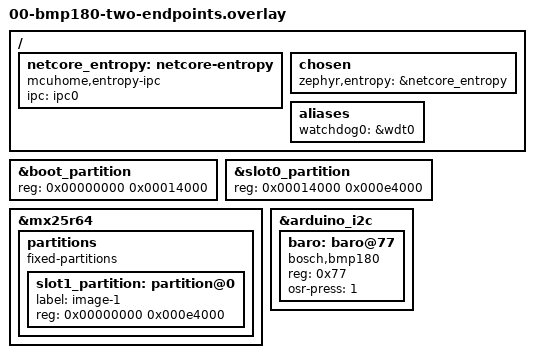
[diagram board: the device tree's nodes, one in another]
/*
 * SPDX-FileCopyrightText: 2026 The MCUHome Contributors
 * SPDX-License-Identifier: Apache-2.0
 *
 * Generated by mcuhome from 00-bmp180-two-endpoints.yaml — do not edit.
 *
 * Board: nrf7002dk/nrf5340/cpuapp.
 *
 * Devicetree description of this device's peripherals. Hardware belongs in devicetree, never in C
 * constants — which is also why a Zephyr sensor driver is enabled by its node here and not by a
 * Kconfig symbol in the fragment next to this file.
 *
 * The blocks before the peripherals are board wiring rather than device configuration: the flash
 * layout and whatever every MCUHome node on this board needs, whatever its YAML says.
 */

/* Flash layout (ADR 0015). MCUHome fixes the partition table itself rather than inheriting the
 * board's, because no upstream default holds an MCUHome image: the two-slot table this board ships
 * with gives the application 464 KiB, and a commissioned Matter node is over 550 KiB.
 * The storage partition keeps the address and size the board's own devicetree gives it. That is
 * what makes an update not a re-commissioning: the Matter fabric credentials and the Thread dataset
 * live there, and every layout in ADR 0015 preserves them.
 * The bootloader image is given the same table, in sysbuild/mcuboot.overlay: the two have to agree
 * on the flash map byte for byte.
 *
 *   mcuboot  internal 0x000000..0x014000    80 KiB
 *   image-0  internal 0x014000..0x0f8000   912 KiB
 *   storage  internal 0x0f8000..0x100000    32 KiB
 *   image-1  mx25r64  0x000000..0x0e4000   912 KiB
 */
/delete-node/ &slot1_partition;

&boot_partition {
	reg = <0x00000000 0x00014000>;
};

&slot0_partition {
	reg = <0x00014000 0x000e4000>;
};

&mx25r64 {
	status = "okay";

	partitions {
		compatible = "fixed-partitions";
		#address-cells = <1>;
		#size-cells = <1>;

		slot1_partition: partition@0 {
			label = "image-1";
			reg = <0x00000000 0x000e4000>;
		};
	};
};

/* Entropy. The nRF5340 application core has no RNG peripheral: the one on the die belongs to the
 * network core. The board default points zephyr,entropy at the Bluetooth HCI entropy driver, which
 * cannot work here because MCUHome runs this SoC Thread-only with Bluetooth off (ADR 0011).
 * Redirect to the framework's IPC driver, which seeds a CTR-DRBG from the network core's real RNG
 * over a second endpoint on the ipc0 instance the 802.15.4 spinel channel already uses.
 * The network core must run mcuhome/samples/netcore-radio for this endpoint to exist; against the
 * upstream 802154_rpmsg image the node comes up and then fails every entropy request with -EIO
 * rather than falling back to a weaker generator.
 * Watchdog. ADR 0015's health amendment makes a hardware watchdog mandatory for every application
 * image, and the framework finds it through the watchdog0 alias (the Zephyr convention). This SoC
 * has the peripheral and this board does not name it, so the alias is board wiring exactly like the
 * entropy redirection above. Without it the build stops with a message naming the alias, rather
 * than producing an image with no watchdog in it. */
/ {
	netcore_entropy: netcore-entropy {
		compatible = "mcuhome,entropy-ipc";
		ipc = <&ipc0>;
		status = "okay";
	};

	chosen {
		zephyr,entropy = &netcore_entropy;
	};

	aliases {
		watchdog0 = &wdt0;
	};
};

&arduino_i2c {
	status = "okay";

	baro: baro@77 {
		compatible = "bosch,bmp180";
		reg = <0x77>;
		osr-press = <1>;
		status = "okay";
	};
};
